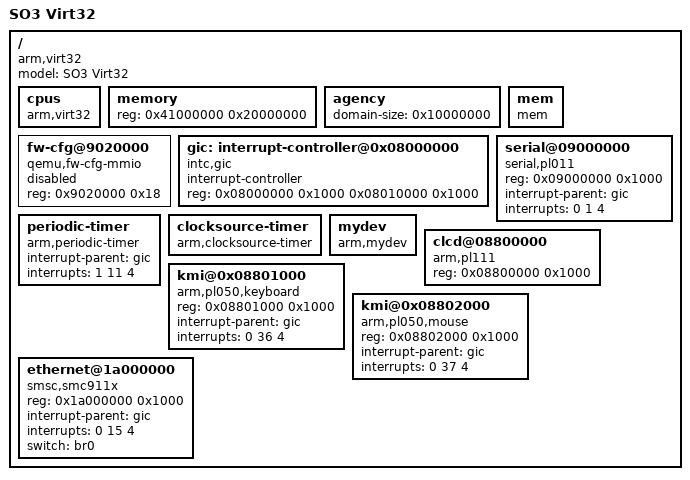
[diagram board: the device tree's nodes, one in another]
/*
 * Copyright (C) 2014-2023 Daniel Rossier <daniel.rossier@heig-vd.ch>
 * 
 * This program is free software; you can redistribute it and/or modify
 * it under the terms of the GNU General Public License version 2 as
 * published by the Free Software Foundation.
 *
 * This program is distributed in the hope that it will be useful,
 * but WITHOUT ANY WARRANTY; without even the implied warranty of
 * MERCHANTABILITY or FITNESS FOR A PARTICULAR PURPOSE.  See the
 * GNU General Public License for more details.
 *
 * You should have received a copy of the GNU General Public License
 * along with this program; if not, write to the Free Software
 * Foundation, Inc., 51 Franklin St, Fifth Floor, Boston, MA  02110-1301  USA
 *
 */
 
/dts-v1/;
 
/ {
	model = "SO3 Virt32";
	compatible = "arm,virt32";

	#address-cells = <1>;
	#size-cells = <1>;

	cpus {
		device_type = "cpu";
		compatible = "arm,virt32";
	};

	memory {
		device_type = "memory";
		reg = <0x41000000 0x20000000>; /* 512 MB */
	};
	
	agency {
	        domain-size = <0x10000000>; /* 256 MB */
	};

	mem {
		compatible = "mem";
		status = "ok";
	};

	fw-cfg@9020000 {
		reg = <0x9020000 0x18>;
		compatible = "qemu,fw-cfg-mmio";
		status = "disabled";
	};
	
	/* GIC interrupt controller */
	gic:interrupt-controller@0x08000000 {
		compatible = "intc,gic";
		interrupt-controller;
		#interrupt-cells = <3>;
		
		reg = <0x08000000 0x1000
			   0x08010000 0x1000>;
			  
		status = "ok";
	};
	
	/* QEMU/virt console UART */
	serial@09000000 {
		compatible = "serial,pl011";
		reg = <0x09000000 0x1000>;
		interrupt-parent = <&gic>;
		interrupts = <0 1 4>;
		status = "ok";
	};

	/* Periodic timer based on ARM CP15 timer */
	periodic-timer {
		compatible = "arm,periodic-timer";
		interrupt-parent = <&gic>;
		interrupts = <1 11 4>;
		status = "ok";
	};
	
	/* Clocksource free-running timer based on ARM CP15 timer */
	clocksource-timer {
		compatible = "arm,clocksource-timer";
		status = "ok";
	};

	mydev {
		compatible = "arm,mydev";
		status = "ok";
	};

	/* PL111 Color LCD Controller
	 *   http://infocenter.arm.com/help/index.jsp?topic=/com.arm.doc.ddi0293c/index.html
	 */
	clcd@08800000{
		compatible = "arm,pl111";
		reg = <0x08800000 0x1000>;

		status = "ok";
	};

	/* PL050 PS2 Keyboard/Mouse Interface
	 *   http://infocenter.arm.com/help/index.jsp?topic=/com.arm.doc.ddi0143c/index.html
	 */
	kmi@0x08801000 { /* keyboard */
		compatible = "arm,pl050,keyboard";
		reg = <0x08801000 0x1000>;
		interrupt-parent = <&gic>;
		interrupts = <0 36 4>;

		status = "ok";
	};

	/* PL050 PS2 Keyboard/Mouse Interface
	 *   http://infocenter.arm.com/help/index.jsp?topic=/com.arm.doc.ddi0143c/index.html
	 */
	kmi@0x08802000 { /* mouse */
		compatible = "arm,pl050,mouse";
		reg = <0x08802000  0x1000>;
		
		interrupt-parent = <&gic>;
		interrupts = <0 37 4>;

		status = "ok";
	};
	
	/*
        https://github.com/psawargaonkar/xvisor-next/blob/95b887c82a37c8d9ee126e061cf4d8f383ec7d01/arch/arm/board/generic/dts/vexpress/a15/vexpress-a15.dtsi
        https://github.com/avpatel/xvisor-next/blob/master/tests/arm32/vexpress-a15/vexpress-a15-guest.dts
   	 */
    ethernet@1a000000 {
        compatible = "smsc,smc911x";
        reg = <0x1a000000 0x1000>;
        
    	interrupt-parent = <&gic>;
        interrupts = <0 15 4>;
        switch = "br0";

        status = "ok";
    };
    	
};
